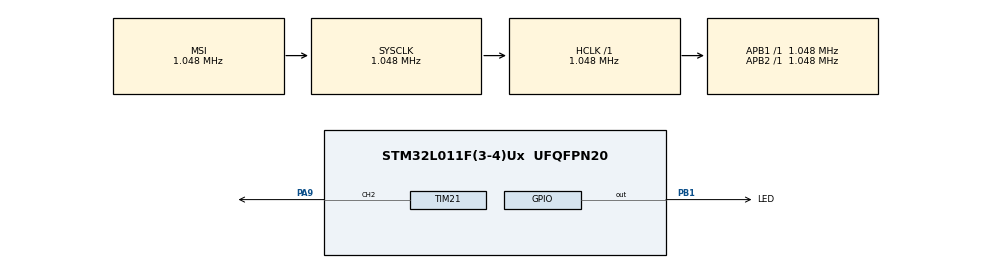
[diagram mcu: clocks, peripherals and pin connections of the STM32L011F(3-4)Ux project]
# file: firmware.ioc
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Mcu.Family=STM32L0
Mcu.Name=STM32L011F(3-4)Ux
Mcu.Package=UFQFPN20
NVIC.TIM21_IRQn=true\:0\:0\:false\:false\:true\:true\:true\:true
NVIC.TIM2_IRQn=true\:0\:0\:false\:false\:true\:true\:true\:true
PA9.Signal=S_TIM21_CH2
PB1.GPIO_Label=LED
PB1.Signal=GPIO_Output
ProjectManager.HeapSize=0x200
ProjectManager.StackSize=0x400
ProjectManager.TargetToolchain=Makefile
RCC.ADCFreq_Value=4000000
RCC.AHBFreq_Value=1048000
RCC.APB1Freq_Value=1048000
RCC.APB1TimFreq_Value=1048000
RCC.APB2Freq_Value=1048000
RCC.APB2TimFreq_Value=1048000
RCC.HCLKFreq_Value=1048000
RCC.HSE_VALUE=8000000
RCC.HSI16_VALUE=16000000
RCC.HSIRCDiv=4
RCC.HSI_VALUE=4000000
RCC.LSE_VALUE=32768
RCC.MSIClockRange=RCC_MSIRANGE_4
RCC.MSI_VALUE=1048000
RCC.PLLDIV=RCC_PLLDIV_4
RCC.PLLMUL=RCC_PLLMUL_4
RCC.SYSCLKFreq_VALUE=1048000
RCC.VCOOutputFreq_Value=16000000
SH.S_TIM21_CH2.0=TIM21_CH2,PWM Generation2 CH2
TIM2.Period=5011
TIM2.Prescaler=1
TIM21.Channel-PWM\ Generation2\ CH2=TIM_CHANNEL_2
TIM21.OCMode_PWM-PWM\ Generation2\ CH2=TIM_OCMODE_PWM2
TIM21.Period=1
TIM21.Prescaler=0
TIM21.Pulse-PWM\ Generation2\ CH2=1
VP_TIM21_VS_ClockSourceINT.Mode=Internal
VP_TIM2_VS_ClockSourceINT.Mode=Internal
board=custom

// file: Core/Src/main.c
/* USER CODE BEGIN Header */
/**
  ******************************************************************************
  * @file           : main.c
  * @brief          : Main program body
  ******************************************************************************
  * @attention
  *
  * <h2><center>&copy; Copyright (c) 2023 STMicroelectronics.
  * All rights reserved.</center></h2>
  *
  * This software component is licensed by ST under BSD 3-Clause license,
  * the "License"; You may not use this file except in compliance with the
  * License. You may obtain a copy of the License at:
  *                        opensource.org/licenses/BSD-3-Clause
  *
  ******************************************************************************
  */
/* USER CODE END Header */
#include "main.h"

/* USER CODE BEGIN Includes */
#include "modulator.h"

/* USER CODE END Includes */

TIM_HandleTypeDef htim2;
TIM_HandleTypeDef htim21;

/* USER CODE BEGIN PV */
bc_handler_struct bc_handler;

/* USER CODE END PV */

void SystemClock_Config(void);
static void MX_GPIO_Init(void);
static void MX_TIM2_Init(void);
static void MX_TIM21_Init(void);

int main(void)
{

  /* MCU Configuration--------------------------------------------------------*/

  /* Reset of all peripherals, Initializes the Flash interface and the Systick. */
  HAL_Init();

  /* Configure the system clock */
  SystemClock_Config();

  /* Initialize all configured peripherals */
  MX_GPIO_Init();
  MX_TIM2_Init();
  MX_TIM21_Init();
  /* USER CODE BEGIN 2 */

	HAL_TIM_OC_Start(&htim21,TIM_CHANNEL_2);
	HAL_TIM_Base_Start_IT(&htim2);

  //  Define time to send one byte
  uint8_t time_per_bit_ms = 1;
  uint16_t time_to_send_one_byte = time_per_bit_ms * 8;

  /* USER CODE END 2 */

  /* Infinite loop */
  while (1)
  {

    /* USER CODE BEGIN 3 */

    //  Create transmit buffer
    uint8_t tx_send_buffer [] = {0xAA, 0xAA, 0x02, 0x23, 0x44, 0xFF};

    //  Backscatter the data
    tx_send(&bc_handler, tx_send_buffer, sizeof(tx_send_buffer));

    //  Minimum delay to send buffer again
    HAL_Delay(sizeof(tx_send_buffer)*time_to_send_one_byte);

    //  Optional, add additional delay between packet transmissions
    HAL_Delay(10);

  }
  /* USER CODE END 3 */
}

void SystemClock_Config(void)
{
  RCC_OscInitTypeDef RCC_OscInitStruct = {0};
  RCC_ClkInitTypeDef RCC_ClkInitStruct = {0};

  /** Configure the main internal regulator output voltage
  */
  __HAL_PWR_VOLTAGESCALING_CONFIG(PWR_REGULATOR_VOLTAGE_SCALE1);
  /** Initializes the RCC Oscillators according to the specified parameters
  * in the RCC_OscInitTypeDef structure.
  */
  RCC_OscInitStruct.OscillatorType = RCC_OSCILLATORTYPE_MSI;
  RCC_OscInitStruct.MSIState = RCC_MSI_ON;
  RCC_OscInitStruct.MSICalibrationValue = 0;
  RCC_OscInitStruct.MSIClockRange = RCC_MSIRANGE_4;
  RCC_OscInitStruct.PLL.PLLState = RCC_PLL_NONE;
  if (HAL_RCC_OscConfig(&RCC_OscInitStruct) != HAL_OK)
  {
    Error_Handler();
  }
  /** Initializes the CPU, AHB and APB buses clocks
  */
  RCC_ClkInitStruct.ClockType = RCC_CLOCKTYPE_HCLK|RCC_CLOCKTYPE_SYSCLK
                              |RCC_CLOCKTYPE_PCLK1|RCC_CLOCKTYPE_PCLK2;
  RCC_ClkInitStruct.SYSCLKSource = RCC_SYSCLKSOURCE_MSI;
  RCC_ClkInitStruct.AHBCLKDivider = RCC_SYSCLK_DIV1;
  RCC_ClkInitStruct.APB1CLKDivider = RCC_HCLK_DIV1;
  RCC_ClkInitStruct.APB2CLKDivider = RCC_HCLK_DIV1;

  if (HAL_RCC_ClockConfig(&RCC_ClkInitStruct, FLASH_LATENCY_0) != HAL_OK)
  {
    Error_Handler();
  }
}

static void MX_TIM2_Init(void)
{

  TIM_ClockConfigTypeDef sClockSourceConfig = {0};
  TIM_MasterConfigTypeDef sMasterConfig = {0};

  htim2.Instance = TIM2;
  htim2.Init.Prescaler = 1;
  htim2.Init.CounterMode = TIM_COUNTERMODE_UP;
  htim2.Init.Period = 511;
  htim2.Init.ClockDivision = TIM_CLOCKDIVISION_DIV1;
  htim2.Init.AutoReloadPreload = TIM_AUTORELOAD_PRELOAD_DISABLE;
  if (HAL_TIM_Base_Init(&htim2) != HAL_OK)
  {
    Error_Handler();
  }
  sClockSourceConfig.ClockSource = TIM_CLOCKSOURCE_INTERNAL;
  if (HAL_TIM_ConfigClockSource(&htim2, &sClockSourceConfig) != HAL_OK)
  {
    Error_Handler();
  }
  sMasterConfig.MasterOutputTrigger = TIM_TRGO_RESET;
  sMasterConfig.MasterSlaveMode = TIM_MASTERSLAVEMODE_DISABLE;
  if (HAL_TIMEx_MasterConfigSynchronization(&htim2, &sMasterConfig) != HAL_OK)
  {
    Error_Handler();
  }

}

static void MX_TIM21_Init(void)
{

  TIM_ClockConfigTypeDef sClockSourceConfig = {0};
  TIM_MasterConfigTypeDef sMasterConfig = {0};
  TIM_OC_InitTypeDef sConfigOC = {0};

  htim21.Instance = TIM21;
  htim21.Init.Prescaler = 0;
  htim21.Init.CounterMode = TIM_COUNTERMODE_UP;
  htim21.Init.Period = 1;
  htim21.Init.ClockDivision = TIM_CLOCKDIVISION_DIV1;
  htim21.Init.AutoReloadPreload = TIM_AUTORELOAD_PRELOAD_DISABLE;
  if (HAL_TIM_Base_Init(&htim21) != HAL_OK)
  {
    Error_Handler();
  }
  sClockSourceConfig.ClockSource = TIM_CLOCKSOURCE_INTERNAL;
  if (HAL_TIM_ConfigClockSource(&htim21, &sClockSourceConfig) != HAL_OK)
  {
    Error_Handler();
  }
  if (HAL_TIM_PWM_Init(&htim21) != HAL_OK)
  {
    Error_Handler();
  }
  sMasterConfig.MasterOutputTrigger = TIM_TRGO_RESET;
  sMasterConfig.MasterSlaveMode = TIM_MASTERSLAVEMODE_DISABLE;
  if (HAL_TIMEx_MasterConfigSynchronization(&htim21, &sMasterConfig) != HAL_OK)
  {
    Error_Handler();
  }
  sConfigOC.OCMode = TIM_OCMODE_PWM2;
  sConfigOC.Pulse = 1;
  sConfigOC.OCPolarity = TIM_OCPOLARITY_HIGH;
  sConfigOC.OCFastMode = TIM_OCFAST_DISABLE;
  if (HAL_TIM_PWM_ConfigChannel(&htim21, &sConfigOC, TIM_CHANNEL_2) != HAL_OK)
  {
    Error_Handler();
  }
  HAL_TIM_MspPostInit(&htim21);

}

static void MX_GPIO_Init(void)
{
  GPIO_InitTypeDef GPIO_InitStruct = {0};

  /* GPIO Ports Clock Enable */
  __HAL_RCC_GPIOB_CLK_ENABLE();
  __HAL_RCC_GPIOA_CLK_ENABLE();

  /*Configure GPIO pin Output Level */
  HAL_GPIO_WritePin(LED_GPIO_Port, LED_Pin, GPIO_PIN_RESET);

  /*Configure GPIO pin : LED_Pin */
  GPIO_InitStruct.Pin = LED_Pin;
  GPIO_InitStruct.Mode = GPIO_MODE_OUTPUT_PP;
  GPIO_InitStruct.Pull = GPIO_NOPULL;
  GPIO_InitStruct.Speed = GPIO_SPEED_FREQ_LOW;
  HAL_GPIO_Init(LED_GPIO_Port, &GPIO_InitStruct);

}

/* USER CODE BEGIN 4 */

uint8_t counter = 0;

// Currently trigger at 104,8 Hz
void HAL_TIM_PeriodElapsedCallback(TIM_HandleTypeDef* htim)
{
	if(htim == &htim2){

    if(bc_handler.status == SENDING){

      uint8_t byte_value = bc_handler.buffer[bc_handler.current_byte];
      uint8_t bit_value = (byte_value >> bc_handler.current_bit) & 0x01;
      // printf("Byte %d, Bit %d: %u\n", current_byte, current_bit, bit_value);

      if(bit_value){
        HAL_TIM_OC_Start(&htim21,TIM_CHANNEL_2);
        HAL_GPIO_WritePin(LED_GPIO_Port, LED_Pin, GPIO_PIN_SET);
      }
      else{
        HAL_TIM_OC_Stop(&htim21,TIM_CHANNEL_2);
        HAL_GPIO_WritePin(LED_GPIO_Port, LED_Pin, GPIO_PIN_RESET);
      }

      // Update current_bit for next interrupt
      if (bc_handler.current_bit > 0) {
          bc_handler.current_bit--;
      } else {
        bc_handler.current_bit = 7;
        bc_handler.current_byte++;
        if (bc_handler.current_byte >= bc_handler.num_bytes) {

            //  Reset after reaching end of buffer
            bc_handler.current_byte = 0;

            //  Update status
            bc_handler.status = IDLE;

            //  Disable timer
            HAL_TIM_OC_Stop(&htim21,TIM_CHANNEL_2);
        }
      }
    }
	}
}

/* USER CODE END 4 */

void Error_Handler(void)
{
  __disable_irq();
  while (1)
  {
  }
}

/************************ (C) COPYRIGHT STMicroelectronics *****END OF FILE****/
